# SIMG301M114LGH register map
Vendor: Silicon Labs; Series: Si; File version: B
Registers are 32-bit, read-write, reset 0x0 unless marked. A register's access mark holds for its fields unless they carry their own. Offsets are from the block's base; [hi:lo] are bit positions.

## PIXELRZ0_NS — PIXELRZ0_NS Registers
Base 0x40860000
Same registers: PIXELRZ1_NS 0x4088C000, PIXELRZ0_S 0x50860000, PIXELRZ1_S 0x5088C000
0x00 IPVERSION ro reset 0x1
  [31:0] IPVERSION — IP version ID
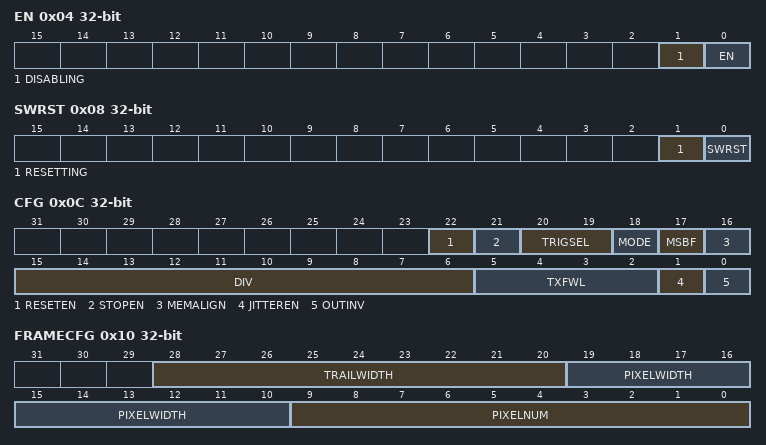
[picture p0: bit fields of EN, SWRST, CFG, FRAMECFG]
0x04 EN
  [1] DISABLING ro — Disablment busy status
  [0] EN — module enable
    0=DISABLE (Disable Peripheral Clock); 1=ENABLE (Enable Peripheral Clock)
0x08 SWRST
  [1] RESETTING ro — Reset busy status
  [0] SWRST wo — Software Reset bit
0x0C CFG
  [22] RESETEN — RESET Symbol Enable
    0=DISABLE (RESET symbols will not be sent); 1=ENABLE (RESET symbols will be sent at the end of each frame)
  [21] STOPEN — STOP Symbol Enable
    0=DISABLE (STOP symbols will not be sent); 1=ENABLE (STOP symbols will be sent at the end of each pixel)
  [20:19] TRIGSEL — Trigger Select
    0=SW (Software trigger mode); 1=AUTO (Auto trigger mode); 2=PRS (PRS trigger mode)
  [18] MODE — Bus Mode
    0=SEQUENTIAL (PIXELRZ formats data for sequential LED connection); 1=PARALLEL (PIXELRZ formats data for parallel LED connection)
  [17] MSBF — MSB First Enable
    0=LSB (Data will be sent LSB-first); 1=MSB (Data will be sent MSB-first)
  [16] MEMALIGN — Memory Alignment
    0=ALIGN8 (Use 8-bit alignment in FIFO); 1=ALIGN32 (Use 32-bit alignment in FIFO)
  [15:6] DIV — Clock Prescaler
  [5:2] TXFWL — TXDATA FIFO Watermark Level
  [1] JITTEREN — Jitter Enable
    0=DISABLE (Jitter generation is disabled); 1=ENABLE (Jitter generation is enabled)
  [0] OUTINV — Invert Output
    0=NORMAL (Output will be logic 0 during low times and logic 1 during high times); 1=INVERT (Output will be logic 1 during low times and logic 0 during high times)
0x10 FRAMECFG
  [28:20] TRAILWIDTH — Trail Data Width
  [19:10] PIXELWIDTH — Pixel Data Width
  [9:0] PIXELNUM — Pixels per Frame
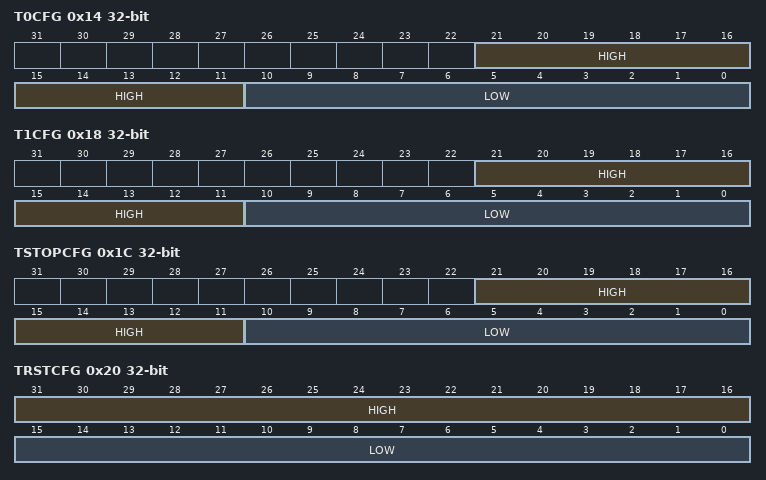
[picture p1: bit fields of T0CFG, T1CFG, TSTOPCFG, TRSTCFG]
0x14 T0CFG
  [21:11] HIGH — Zero symbol High Time
  [10:0] LOW — Zero symbol Low Time
0x18 T1CFG
  [21:11] HIGH — One Symbol High Time
  [10:0] LOW — One Symbol Low Time
0x1C TSTOPCFG
  [21:11] HIGH — Stop Symbol High Time
  [10:0] LOW — Stop Symbol Low Time
0x20 TRSTCFG
  [31:16] HIGH — Reset Symbol High Time
  [15:0] LOW — Reset Symbol Low Time
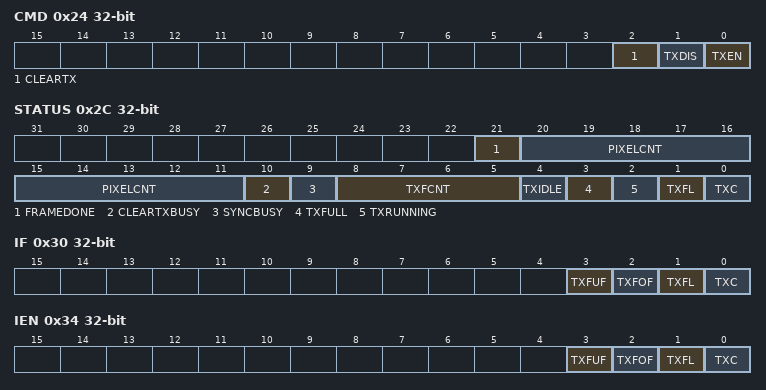
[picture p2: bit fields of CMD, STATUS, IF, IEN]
0x24 CMD wo
  [2] CLEARTX — Clear TX fifo
  [1] TXDIS — Send stop condition
  [0] TXEN — Send start condition
0x28 TXDATA wo
  [31:0] TXDATA — TX Data FIFO
0x2C STATUS ro
  [21] FRAMEDONE
  [20:11] PIXELCNT — Pixel Count
  [10] CLEARTXBUSY — Clear TX Command Busy
  [9] SYNCBUSY
  [8:5] TXFCNT — FIFO Count
  [4] TXIDLE — Transmitter Idle
  [3] TXFULL — TX FIFO full
  [2] TXRUNNING — TX in Progress
  [1] TXFL — TX FIFO Watermark
  [0] TXC — TX Complete
0x30 IF
  [3] TXFUF — Underflow
  [2] TXFOF — Overflow
  [1] TXFL — Reached watermark
  [0] TXC — Transmission complete
0x34 IEN
  [3] TXFUF — Underflow interrupt enable
  [2] TXFOF — Overflow interrupt enable
  [1] TXFL — Reached watermark interrupt enable
  [0] TXC — Transmission complete interrupt enable

## RPA_NS — RPA_NS Registers
Base 0x40898000
Same registers: RPA_S 0x50898000
0x00 IPVERSION ro reset 0x1
  [31:0] IPVERSION — IP version ID
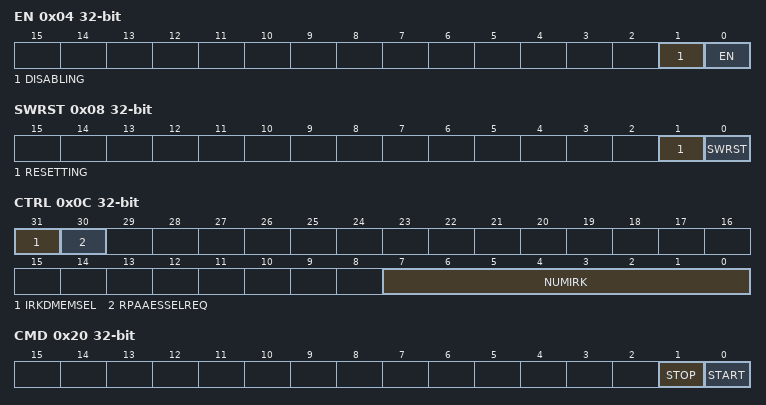
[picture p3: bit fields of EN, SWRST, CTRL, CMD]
0x04 EN
  [1] DISABLING ro — Disablement busy status
  [0] EN — Module enable
0x08 SWRST
  [1] RESETTING ro — Software reset command
  [0] SWRST wo — Status of reset
0x0C CTRL
  [31] IRKDMEMSEL — Selects DMEM IRKs
  [30] RPAAESSELREQ — Preemption request
  [7:0] NUMIRK — Number of IRKs
0x10 PRAND
  [23:0] PRAND
0x14 HASH
  [23:0] HASH
0x18 IRKADDR
  [31:0] IRKADDR — IRK address
0x1C IRKKEYSLOTID
  [7:0] IRKKEYSLOTID
0x20 CMD wo
  [1] STOP — Stop RPA
  [0] START — Start RPA
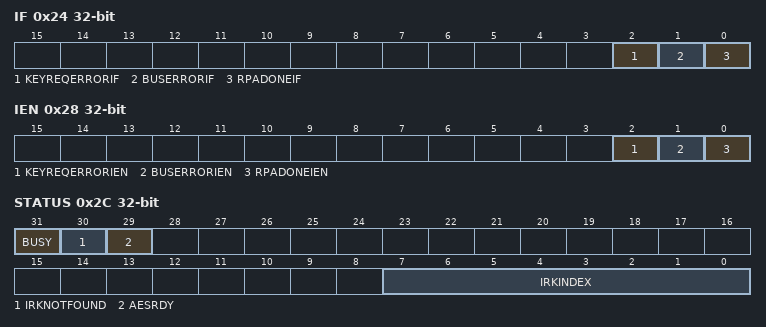
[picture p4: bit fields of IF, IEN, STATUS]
0x24 IF
  [2] KEYREQERRORIF — Key request error IF
  [1] BUSERRORIF
  [0] RPADONEIF
0x28 IEN
  [2] KEYREQERRORIEN — Enable key request error IF
  [1] BUSERRORIEN — Enable bus error IF
  [0] RPADONEIEN — Enable RPA done IF
0x2C STATUS ro
  [31] BUSY — RPA busy
  [30] IRKNOTFOUND
  [29] AESRDY — AES ready
  [7:0] IRKINDEX
0x80 IRKMASK0 reset 0xFFFFFFFF
  [31:0] IRKMASK — IRK masks
